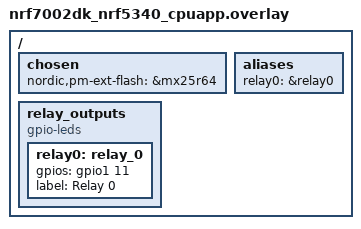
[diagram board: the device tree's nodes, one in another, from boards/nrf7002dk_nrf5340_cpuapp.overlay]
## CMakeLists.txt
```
cmake_minimum_required(VERSION 3.20.0)

find_package(Zephyr REQUIRED HINTS $ENV{ZEPHYR_BASE})
find_package(Python REQUIRED COMPONENTS Interpreter)
find_program(BUN_EXECUTABLE bun REQUIRED)
project(lnh_nordic_wifi)

set(APP_SOURCE_ROOT ${CMAKE_CURRENT_SOURCE_DIR}/src)

set(APP_SOURCES
	${APP_SOURCE_ROOT}/main.c
	${APP_SOURCE_ROOT}/app/bootstrap.c
	${APP_SOURCE_ROOT}/actions/actions.c
	${APP_SOURCE_ROOT}/network/network_supervisor.c
	${APP_SOURCE_ROOT}/network/wifi_lifecycle.c
	${APP_SOURCE_ROOT}/network/reachability.c
	${APP_SOURCE_ROOT}/panel/panel_auth.c
	${APP_SOURCE_ROOT}/panel/panel_http.c
	${APP_SOURCE_ROOT}/panel/panel_status.c
	${APP_SOURCE_ROOT}/ota/ota.c
	${APP_SOURCE_ROOT}/persistence/persistence.c
	${APP_SOURCE_ROOT}/relay/relay.c
	${APP_SOURCE_ROOT}/recovery/recovery.c
	${APP_SOURCE_ROOT}/scheduler/scheduler.c
)

target_sources(app PRIVATE ${APP_SOURCES})

target_include_directories(app PRIVATE ${APP_SOURCE_ROOT})

zephyr_linker_sources(SECTIONS sections-rom.ld)
zephyr_linker_section(NAME http_resource_desc_panel_http_service
	KVMA RAM_REGION GROUP RODATA_REGION)

set(PANEL_ASSET_SOURCE_DIR ${APP_SOURCE_ROOT}/panel/assets)
set(PANEL_ASSET_GENERATED_DIR ${ZEPHYR_BINARY_DIR}/include/generated/panel)
set(PANEL_ASSET_BUILD_DIR ${ZEPHYR_BINARY_DIR}/panel-assets)
set(PANEL_INDEX_HTML_SOURCE ${PANEL_ASSET_SOURCE_DIR}/index.html)
set(PANEL_LOGIN_HTML_SOURCE ${PANEL_ASSET_SOURCE_DIR}/login.html)
set(PANEL_OVERVIEW_HTML_SOURCE ${PANEL_ASSET_SOURCE_DIR}/overview.html)
set(PANEL_ACTION_EDITOR_HTML_SOURCE ${PANEL_ASSET_SOURCE_DIR}/action-editor.html)
set(PANEL_SCHEDULES_HTML_SOURCE ${PANEL_ASSET_SOURCE_DIR}/schedules.html)
set(PANEL_SCHEDULE_EDITOR_HTML_SOURCE ${PANEL_ASSET_SOURCE_DIR}/schedule-editor.html)
set(PANEL_UPDATES_HTML_SOURCE ${PANEL_ASSET_SOURCE_DIR}/updates.html)
set(PANEL_CSS_SOURCE ${PANEL_ASSET_SOURCE_DIR}/panel.css)
set(PANEL_MAIN_JS_SOURCE ${PANEL_ASSET_SOURCE_DIR}/main.js)
set(PANEL_MAIN_JS_MINIFIED ${PANEL_ASSET_BUILD_DIR}/main.min.js)

file(MAKE_DIRECTORY ${PANEL_ASSET_GENERATED_DIR})
file(MAKE_DIRECTORY ${PANEL_ASSET_BUILD_DIR})

add_custom_command(
	OUTPUT ${PANEL_MAIN_JS_MINIFIED}
	COMMAND ${CMAKE_COMMAND} -E make_directory ${PANEL_ASSET_BUILD_DIR}
	COMMAND
		${BUN_EXECUTABLE}
		build
		${PANEL_MAIN_JS_SOURCE}
		--target=browser
		--format=iife
		--minify
		--outfile
		${PANEL_MAIN_JS_MINIFIED}
	DEPENDS ${PANEL_MAIN_JS_SOURCE}
	COMMENT "Minifying panel JavaScript with Bun"
	VERBATIM
)

set_source_files_properties(${PANEL_MAIN_JS_MINIFIED} PROPERTIES GENERATED TRUE)

generate_inc_file_for_target(
	app
	${PANEL_INDEX_HTML_SOURCE}
	${PANEL_ASSET_GENERATED_DIR}/index.html.gz.inc
	--gzip
)

generate_inc_file_for_target(
	app
	${PANEL_LOGIN_HTML_SOURCE}
	${PANEL_ASSET_GENERATED_DIR}/login.html.gz.inc
	--gzip
)

generate_inc_file_for_target(
	app
	${PANEL_OVERVIEW_HTML_SOURCE}
	${PANEL_ASSET_GENERATED_DIR}/overview.html.gz.inc
	--gzip
)

generate_inc_file_for_target(
	app
	${PANEL_ACTION_EDITOR_HTML_SOURCE}
	${PANEL_ASSET_GENERATED_DIR}/action-editor.html.gz.inc
	--gzip
)

generate_inc_file_for_target(
	app
	${PANEL_SCHEDULES_HTML_SOURCE}
	${PANEL_ASSET_GENERATED_DIR}/schedules.html.gz.inc
	--gzip
)

generate_inc_file_for_target(
	app
	${PANEL_SCHEDULE_EDITOR_HTML_SOURCE}
	${PANEL_ASSET_GENERATED_DIR}/schedule-editor.html.gz.inc
	--gzip
)

generate_inc_file_for_target(
	app
	${PANEL_UPDATES_HTML_SOURCE}
	${PANEL_ASSET_GENERATED_DIR}/updates.html.gz.inc
	--gzip
)

generate_inc_file_for_target(
	app
	${PANEL_CSS_SOURCE}
	${PANEL_ASSET_GENERATED_DIR}/panel.css.gz.inc
	--gzip
)

generate_inc_file_for_target(
	app
	${PANEL_MAIN_JS_MINIFIED}
	${PANEL_ASSET_GENERATED_DIR}/main.js.gz.inc
	--gzip
)
```

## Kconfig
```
source "Kconfig.zephyr"

menu "LNH Nordic"

config APP_WIFI_SSID
	string "Wi-Fi SSID"
	default ""

config APP_WIFI_PSK
	string "Wi-Fi password"
	default ""

config APP_WIFI_SECURITY
	string "Wi-Fi security mode"
	default "psk"
	help
	  Supported values: none, psk, psk-sha256, sae.

config APP_WIFI_TIMEOUT_MS
	int "Overall Wi-Fi timeout in milliseconds"
	default 90000
	range 1000 600000

config APP_WIFI_RETRY_INTERVAL_MS
	int "Wi-Fi reconnect retry interval in milliseconds"
	default 5000
	range 1000 600000
	help
	  Retry cadence used by the network supervisor after startup or runtime
	  network degradation.

config APP_REACHABILITY_HOST
	string "Hostname used for post-connect reachability check"
	default "example.com"

config APP_RECOVERY_WATCHDOG_TIMEOUT_MS
	int "Recovery watchdog timeout in milliseconds"
	default 30000
	range 1000 600000
	help
	  Hardware watchdog timeout serviced by the recovery manager only while
	  supervised execution paths remain inside their allowed windows.

config APP_RECOVERY_DEGRADED_PATIENCE_MS
	int "Recovery degraded patience window in milliseconds"
	default 120000
	range 1000 3600000
	help
	  Maximum continuous degraded or no-progress window before recovery
	  treats the condition as confirmed stuck.

config APP_RECOVERY_STABLE_WINDOW_MS
	int "Recovery stable-run clearing window in milliseconds"
	default 30000
	range 1000 600000
	help
	  Acceptable-runtime duration required before a prior recovery incident is
	  considered cleared.

config APP_RECOVERY_COOLDOWN_MS
	int "Recovery anti-thrash cooldown in milliseconds"
	default 180000
	range 1000 3600000
	help
	  Minimum suppression window after a recovery-triggered reboot before
	  another escalation may be considered.

config APP_PERSISTENCE_LAYOUT_VERSION
	int "Persistent configuration layout version"
	default 2
	range 1 255
	help
	  Schema layout version for the persisted configuration contracts.

config APP_SCHEDULER_CADENCE_SECONDS
	int "Scheduler cadence in seconds"
	default 60
	range 60 60
	help
	  Phase 7 scheduling evaluates normalized UTC time at minute resolution
	  only. This fixed cadence anchors future scheduler work ownership.

config APP_SCHEDULER_TRUSTED_CLOCK_TIMEOUT_MS
	int "Trusted-clock acquisition timeout in milliseconds"
	default 15000
	range 1000 600000
	help
	  Maximum window reserved for Phase 7 trusted-clock ownership before
	  later plans decide whether automation must remain degraded.

config APP_SCHEDULER_TRUSTED_CLOCK_SERVER
	string "Trusted-clock SNTP server"
	default "time.google.com"
	help
	  Fallback SNTP server used when DHCP does not provide an NTP server.
	  The scheduler owns trusted-clock acquisition directly in Phase 7 and
	  uses this server only for one-shot synchronization attempts.

config APP_RELAY_REBOOT_POLICY_DEFAULT
	int "Clean-device relay reboot policy"
	default 0
	range 0 2
	help
	  0 keeps the relay safely off after reboot until runtime configuration is
	  saved. 1 restores the last desired relay state. 2 ignores the last desired
	  state and leaves runtime relay control to later boot logic.

config APP_ADMIN_USERNAME
	string "Admin username"
	default ""

config APP_ADMIN_PASSWORD
	string "Admin password"
	default ""

config APP_PANEL_PORT
	int "Local control panel HTTP port"
	default 80
	range 1 65535
	help
	  Plain HTTP port exposed by the device on the local LAN for the Phase 5
	  control panel shell.

config APP_PANEL_REQUEST_TIMEOUT_SECONDS
	int "Panel HTTP request timeout in seconds"
	default 10
	range 1 600
	help
	  Maximum inactivity window allowed for a panel HTTP request before the
	  underlying Zephyr HTTP server closes the client connection. Keep this
	  aligned with the operator-facing page navigation timeout.

configdefault HTTP_SERVER_CLIENT_INACTIVITY_TIMEOUT
	default APP_PANEL_REQUEST_TIMEOUT_SECONDS if HTTP_SERVER

config APP_PANEL_MAX_SESSIONS
	int "Maximum concurrent panel sessions"
	default 4
	range 1 8
	help
	  Maximum number of concurrent RAM-only browser sessions allowed for the
	  single local operator account.

config APP_PANEL_LOGIN_FAILURE_LIMIT
	int "Wrong-password attempts before cooldown"
	default 5
	range 1 20
	help
	  Consecutive wrong-password attempts allowed before the panel enters a
	  temporary login cooldown.

config APP_PANEL_LOGIN_COOLDOWN_MS
	int "Panel login cooldown in milliseconds"
	default 30000
	range 1000 600000
	help
	  Cooldown applied after repeated wrong-password attempts.

config APP_OTA_CONFIRM_STABLE_WINDOW_MS
	int "OTA confirmation stable window in milliseconds"
	default 15000
	range 1000 600000
	help
	  Healthy post-boot window the firmware must survive after APP_READY
	  before a test image is marked permanent.

config APP_OTA_REMOTE_DEFAULT_CHECK_INTERVAL_HOURS
	int "Default remote OTA check interval in hours"
	default 24
	range 1 168
	help
	  Default cadence for daily GitHub Release checks when remote OTA is
	  enabled in persistence.

config APP_OTA_REMOTE_GITHUB_OWNER
	string "Default OTA GitHub owner"
	default "lukasa1993"
	help
	  GitHub Releases owner used by the built-in remote OTA flow.

config APP_OTA_REMOTE_GITHUB_REPO
	string "Default OTA GitHub repo"
	default "L-Controller"
	help
	  GitHub Releases repository used by the built-in remote OTA flow.

endmenu
```

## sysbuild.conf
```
SB_CONFIG_BOOTLOADER_MCUBOOT=y
SB_CONFIG_WIFI_NRF70=y
```

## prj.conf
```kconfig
CONFIG_NETWORKING=y
CONFIG_NET_IPV4=y
CONFIG_NET_DHCPV4=y
CONFIG_NET_TCP=y
CONFIG_NET_UDP=y
CONFIG_NET_SOCKETS=y
CONFIG_NET_SOCKETS_SOCKOPT_TLS=y
CONFIG_NET_MAX_CONN=10
CONFIG_DNS_RESOLVER=y
CONFIG_NET_L2_ETHERNET=y
CONFIG_NET_CONTEXT_SYNC_RECV=y
CONFIG_NET_MAX_CONTEXTS=10
CONFIG_NET_IF_UNICAST_IPV4_ADDR_COUNT=1
CONFIG_NET_PKT_RX_COUNT=16
CONFIG_NET_PKT_TX_COUNT=16
CONFIG_NET_BUF_RX_COUNT=16
CONFIG_NET_BUF_TX_COUNT=32
CONFIG_NET_TCP_TIME_WAIT_DELAY=0
CONFIG_NET_MGMT_EVENT_QUEUE_TIMEOUT=5000

CONFIG_WIFI=y
CONFIG_WIFI_NRF70=y
CONFIG_WIFI_NM_WPA_SUPPLICANT=y
CONFIG_WIFI_READY_LIB=y
CONFIG_NRF_WIFI_RPU_RECOVERY=y
CONFIG_NRF70_RX_NUM_BUFS=16

CONFIG_MAIN_STACK_SIZE=6144
CONFIG_NET_TX_STACK_SIZE=4096
CONFIG_NET_RX_STACK_SIZE=4096
CONFIG_HEAP_MEM_POOL_SIZE=43000
CONFIG_HEAP_MEM_POOL_IGNORE_MIN=y
CONFIG_NRF_WIFI_CTRL_HEAP_SIZE=20000
CONFIG_NRF_WIFI_DATA_HEAP_SIZE=40000
CONFIG_NET_TC_TX_COUNT=1

CONFIG_LOG=y
CONFIG_LOG_DEFAULT_LEVEL=3
CONFIG_LOG_BUFFER_SIZE=2048
CONFIG_CONSOLE=y
CONFIG_SERIAL=y
CONFIG_PRINTK=y
CONFIG_POSIX_TIMERS=y
CONFIG_REBOOT=y
CONFIG_WATCHDOG=y
CONFIG_HWINFO=y
CONFIG_GPIO=y
CONFIG_FLASH=y
CONFIG_FLASH_MAP=y
CONFIG_FLASH_PAGE_LAYOUT=y
CONFIG_STREAM_FLASH=y
CONFIG_IMG_MANAGER=y
CONFIG_IMG_ERASE_PROGRESSIVELY=y
CONFIG_NVS=y
CONFIG_SPI=y
CONFIG_SPI_NOR=y
CONFIG_SPI_NOR_SFDP_DEVICETREE=y
CONFIG_SPI_NOR_FLASH_LAYOUT_PAGE_SIZE=4096
CONFIG_DOWNLOADER=y
CONFIG_DOWNLOADER_STACK_SIZE=4096
CONFIG_DOWNLOADER_MAX_HOSTNAME_SIZE=128
CONFIG_DOWNLOADER_MAX_FILENAME_SIZE=384
CONFIG_TLS_CREDENTIALS=y
CONFIG_TLS_CREDENTIALS_BACKEND_VOLATILE=y
CONFIG_MBEDTLS_RSA_C=y
CONFIG_MBEDTLS_X509_CRT_PARSE_C=y
CONFIG_MBEDTLS_SSL_SERVER_NAME_INDICATION=y
CONFIG_WARN_EXPERIMENTAL=n
CONFIG_WARN_DEPRECATED=n
CONFIG_BOOTLOADER_MCUBOOT=y
CONFIG_APP_SCHEDULER_CADENCE_SECONDS=60
CONFIG_APP_SCHEDULER_TRUSTED_CLOCK_TIMEOUT_MS=15000
CONFIG_APP_SCHEDULER_TRUSTED_CLOCK_SERVER="time.google.com"
CONFIG_SNTP=y
CONFIG_NET_DHCPV4_OPTION_NTP_SERVER=y

CONFIG_JSON_LIBRARY=y

CONFIG_HTTP_SERVER=y
CONFIG_HTTP_CLIENT=y
CONFIG_APP_PANEL_REQUEST_TIMEOUT_SECONDS=10
CONFIG_HTTP_SERVER_NUM_SERVICES=1
CONFIG_HTTP_SERVER_MAX_CLIENTS=4
CONFIG_HTTP_SERVER_STACK_SIZE=12288
CONFIG_HTTP_SERVER_CLIENT_BUFFER_SIZE=2048
CONFIG_HTTP_SERVER_MAX_HEADER_LEN=256
CONFIG_HTTP_SERVER_CAPTURE_HEADERS=y
CONFIG_HTTP_SERVER_CAPTURE_HEADER_BUFFER_SIZE=256
CONFIG_HTTP_SERVER_CAPTURE_HEADER_COUNT=4

CONFIG_INIT_STACKS=y
CONFIG_STACK_SENTINEL=y
CONFIG_ENTROPY_GENERATOR=y
```

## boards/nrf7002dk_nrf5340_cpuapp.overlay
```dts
#include <zephyr/dt-bindings/gpio/gpio.h>

/*
 * Route Partition Manager to the board's MX25R64 so slot-1 can live off-chip,
 * while preserving the board-owned relay0 binding from Phase 6.
 */

/ {
	chosen {
		nordic,pm-ext-flash = &mx25r64;
	};

	aliases {
		relay0 = &relay0;
	};

	relay_outputs {
		compatible = "gpio-leds";

		relay0: relay_0 {
			gpios = <&gpio1 11 GPIO_ACTIVE_HIGH>;
			label = "Relay 0";
		};
	};
};
```

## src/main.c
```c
#include <zephyr/kernel.h>
#include <zephyr/logging/log.h>

#include "app/bootstrap.h"

LOG_MODULE_REGISTER(app, CONFIG_LOG_DEFAULT_LEVEL);

static struct app_context app_context;

int main(void)
{
	int ret;

	ret = app_boot(&app_context);
	if (ret != 0) {
		return ret;
	}

	for (;;) {
		k_sleep(K_SECONDS(1));
	}
}
```
